# nrf54lm20a_enga_application register map
Vendor: Nordic Semiconductor; Series: nrf54l; File version: 1
CPU: CM33 r0p4, little endian, MPU, FPU, 3 interrupt priority bits, 270 interrupts, 4 SAU regions
Registers are 32-bit, read-write, reset 0x0 unless marked. A register's access mark holds for its fields unless they carry their own. Offsets are from the block's base; [hi:lo] are bit positions; lines under a group give offsets from that group; 'fields as' and 'values as' point back to an identical list.

## GLOBAL_VREGUSB_NS — VREGUSB peripheral 0
Base 0x40121000
Same registers: GLOBAL_VREGUSB_S 0x50121000
0x00 TASKS_START wo — Enable and start VREGUSB so that it can detect VBUS
  [0] TASKS_START
    1=Trigger task
0x04 TASKS_STOP wo — Stop and disable VREGUSB
  [0] TASKS_STOP
    1=Trigger task
0x100 EVENTS_VBUSDETECTEDRAW — VBUS detected
  [0] EVENTS_VBUSDETECTEDRAW
    0=NotGenerated (Event not generated); 1=Generated (Event generated)
0x104 EVENTS_VBUSDETECTED — VBUS detected
  [0] EVENTS_VBUSDETECTED
    values as EVENTS_VBUSDETECTEDRAW.EVENTS_VBUSDETECTEDRAW
0x110 EVENTS_VBUSREMOVED — VBUS removed
  [0] EVENTS_VBUSREMOVED
    values as EVENTS_VBUSDETECTEDRAW.EVENTS_VBUSDETECTEDRAW
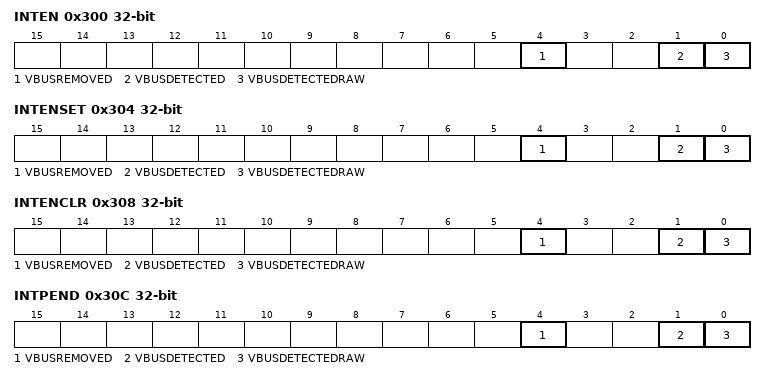
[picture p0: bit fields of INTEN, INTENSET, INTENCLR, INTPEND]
0x300 INTEN — Enable or disable interrupt
  [all] fields
    0=Disabled; 1=Enabled
  [4] VBUSREMOVED — Enable or disable interrupt for event VBUSREMOVED
  [1] VBUSDETECTED — Enable or disable interrupt for event VBUSDETECTED
  [0] VBUSDETECTEDRAW — Enable or disable interrupt for event VBUSDETECTEDRAW
0x304 INTENSET — Enable interrupt
  [all] fields
    on read: 0=Disabled (Read: Disabled); 1=Enabled (Read: Enabled) | on write: 1=Set (Enable)
  [4] VBUSREMOVED — Write '1' to enable interrupt for event VBUSREMOVED
  [1] VBUSDETECTED — Write '1' to enable interrupt for event VBUSDETECTED
  [0] VBUSDETECTEDRAW — Write '1' to enable interrupt for event VBUSDETECTEDRAW
0x308 INTENCLR — Disable interrupt
  [all] fields
    on read: 0=Disabled (Read: Disabled); 1=Enabled (Read: Enabled) | on write: 1=Clear (Disable)
  [4] VBUSREMOVED — Write '1' to disable interrupt for event VBUSREMOVED
  [1] VBUSDETECTED — Write '1' to disable interrupt for event VBUSDETECTED
  [0] VBUSDETECTEDRAW — Write '1' to disable interrupt for event VBUSDETECTEDRAW
0x30C INTPEND ro — Pending interrupts
  [all] fields
    on read: 0=NotPending (Read: Not pending); 1=Pending (Read: Pending)
  [4] VBUSREMOVED — Read pending status of interrupt for event VBUSREMOVED
  [1] VBUSDETECTED — Read pending status of interrupt for event VBUSDETECTED
  [0] VBUSDETECTEDRAW — Read pending status of interrupt for event VBUSDETECTEDRAW
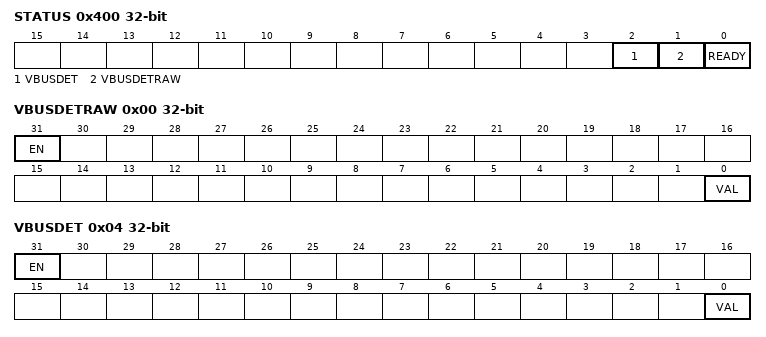
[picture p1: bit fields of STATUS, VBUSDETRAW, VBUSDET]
0x400 STATUS ro — Status of USB PM
  [2] VBUSDET — VBUS detected, filtered
    0=NotVbusDet (VBUS not detected); 1=VBUS detected
  [1] VBUSDETRAW — VBUS detected, raw signal
    0=NotVbusDetRaw (VBUS not detected); 1=VbusDetRaw (VBUS detected)
  [0] READY — USB PM ready
    0=PowerDown (USB PM powered down); 1=Powered (USB PM powered up)
0x410 CONFIG group — Unspecified
  0x00 RDYTIM reset 0x18 — Time from pwrupPm to ready signal (0us-3us)
    [5:0] VAL — Timer value
      0=Min (0 us); 24=Default (1.5 us); 48=Max (3 us)
  0x04 VBRFT reset 0xA0 — Time from VBUSDETRAW until filtered VBUSDET (0us-500us)
    [12:0] VAL — Timer value
      0=Min (0 us); 160=Default (10 us); 0x1F40=Max (500 us)
  0x08 RDYLDOSTIM reset 0x10 — Time from powerup LDOs until ready (0us-10us)
    [7:0] VAL — Timer value
      0=Min (0 us); 10=Default (1 us); 160=Max (10 us)
0x44C TRIM group — Unspecified
  0x00 TRIM3V3 reset 0x8 — Trim USB PHY 3.3V VDD
    [4:0] VAL — Voltage offset trimming value
0x480 MIRROR — Enable LOCK for mirrored registers
  [0] LOCK — Enable analog retention locally in peripheral
    0=Disabled (Lock disabled); 1=Enabled (Lock enabled)
0x500 OVERRIDE group — Unspecified
  0x00 VBUSDETRAW — Override the raw VBUSDET from the analog module
    [31] EN — Enable the override
      0=Disabled (Override is disabled); 1=Enabled (Override is enabled)
    [0] VAL — Override value for the signal
  0x04 VBUSDET — Override the filtered VBUSDET from the digital part
    fields as OVERRIDE.VBUSDETRAW
0x600 DFT group — Unspecified
  0x00 ATB0CONFIG — Analog Test Bus 0 (ATB0) configuration
    [1:0] ATB0CFG
      0=HiZ (Allow other IPs to use ATB0); 1=VoutDiv3 (Regulator output voltage divided by 3); 2=VbgInt (Bandgap reference voltage); 3=Vss (Ground)
  0x04 ATB1CONFIG — Analog Test Bus 1 (ATB1) configuration
    [1:0] ATB1CFG
      0=HiZ (Allow other IPs to use ATB1); 1=Vss (Ground); 2=VssInt (Voltage regulator ground)
  0x10 DTB0CONFIG — Digital Test Bus 0 (DTB0) configuration
    [0] DTB0CFG — Digital testbus 0 configuration
      0=Dtb0Low (Allow other IPsto use DTB0); 1=VBUS detector output, VBUS_DET
